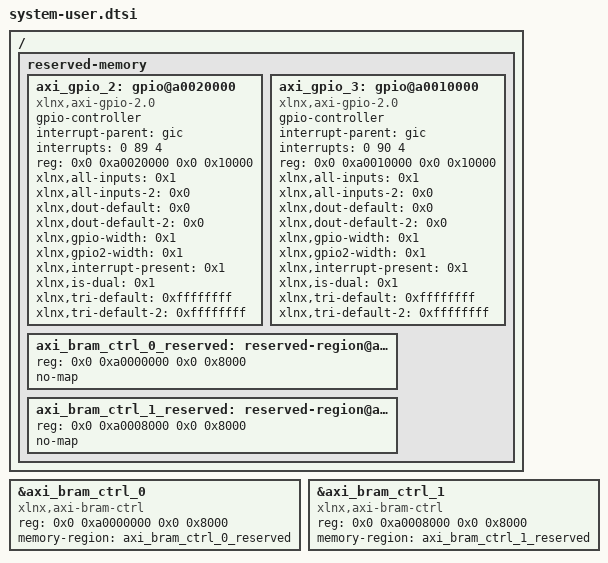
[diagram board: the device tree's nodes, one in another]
/include/ "system-conf.dtsi"

/ {
   #address-cells = <2>;
   #size-cells = <2>;

   reserved-memory {
       ranges;


   // GPIO 0 configuration
   axi_gpio_2: gpio@a0020000 {
       #gpio-cells = <2>;
       compatible = "xlnx,axi-gpio-2.0", "xlnx,xps-gpio-1.00.a";
       gpio-controller ;
       interrupt-parent = <&gic>;
       interrupts = <0 89 4>;
       reg = <0x0 0xa0020000 0x0 0x10000>;
       xlnx,all-inputs = <0x1>;
       xlnx,all-inputs-2 = <0x0>;
       xlnx,dout-default = <0x0>;
       xlnx,dout-default-2 = <0x0>;
       xlnx,gpio-width = <0x1>;
       xlnx,gpio2-width = <0x1>;
       xlnx,interrupt-present = <0x1>;
       xlnx,is-dual = <0x1>;
       xlnx,tri-default = <0xffffffff>;
       xlnx,tri-default-2 = <0xffffffff>;
   } ;
   
   axi_gpio_3: gpio@a0010000 {
       #gpio-cells = <2>;
       compatible = "xlnx,axi-gpio-2.0", "xlnx,xps-gpio-1.00.a";
       gpio-controller ;
       interrupt-parent = <&gic>;
       interrupts = <0 90 4>;
       reg = <0x0 0xa0010000 0x0 0x10000>;
       xlnx,all-inputs = <0x1>;
       xlnx,all-inputs-2 = <0x0>;
       xlnx,dout-default = <0x0>;
       xlnx,dout-default-2 = <0x0>;
       xlnx,gpio-width = <0x1>;
       xlnx,gpio2-width = <0x1>;
       xlnx,interrupt-present = <0x1>;
       xlnx,is-dual = <0x1>;
       xlnx,tri-default = <0xffffffff>;
       xlnx,tri-default-2 = <0xffffffff>;
   } ;


       axi_bram_ctrl_0_reserved: reserved-region@a0000000 {
           reg = <0x0 0xa0000000 0x0 0x8000>; // 32 KB for axi_bram_ctrl_0
           no-map;
       };

       axi_bram_ctrl_1_reserved: reserved-region@a0008000 {
           reg = <0x0 0xa0008000 0x0 0x8000>; // 32 KB for axi_bram_ctrl_1
           no-map;
       };
   };
};

&axi_bram_ctrl_0 {
    compatible = "xlnx,axi-bram-ctrl"; // Adjust to match your device's compatible string
    reg = <0x0 0xa0000000 0x0 0x8000>; // Base address and range for axi_bram_ctrl_0
    memory-region = <&axi_bram_ctrl_0_reserved>;
    status = "okay";
};

&axi_bram_ctrl_1 {
    compatible = "xlnx,axi-bram-ctrl"; // Adjust to match your device's compatible string
    reg = <0x0 0xa0008000 0x0 0x8000>; // Base address and range for axi_bram_ctrl_1
    memory-region = <&axi_bram_ctrl_1_reserved>;
    status = "okay";
};
